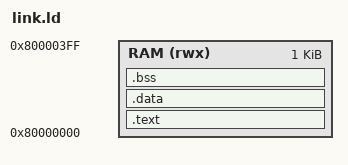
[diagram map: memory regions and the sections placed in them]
ENTRY(_start)

MEMORY
{
    RAM (rwx) : ORIGIN = 0x80000000, LENGTH = 1024
}

SECTIONS
{
    .text : {
        *(.text*)
        *(.rodata*)
    } > RAM

    .data : {
        *(.data*)
    } > RAM

    .bss : {
        *(.bss*)
        *(COMMON)
    } > RAM
}
